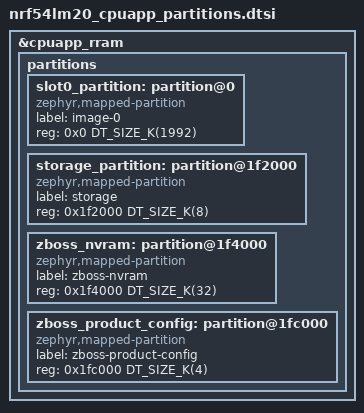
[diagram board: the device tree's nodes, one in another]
/*
 * Copyright (c) 2026 Nordic Semiconductor ASA
 *
 * SPDX-License-Identifier: LicenseRef-Nordic-5-Clause
 */

/delete-node/ &boot_partition;
/delete-node/ &slot0_partition;
/delete-node/ &slot1_partition;
/delete-node/ &storage_partition;

&cpuapp_rram {
	partitions {
		slot0_partition: partition@0 {
			compatible = "zephyr,mapped-partition";
			label = "image-0";
			reg = <0x0 DT_SIZE_K(1992)>;
		};

		storage_partition: partition@1f2000 {
			compatible = "zephyr,mapped-partition";
			label = "storage";
			reg = <0x1f2000 DT_SIZE_K(8)>;
		};

		zboss_nvram: partition@1f4000 {
			compatible = "zephyr,mapped-partition";
			label = "zboss-nvram";
			reg = <0x1f4000 DT_SIZE_K(32)>;
		};

		zboss_product_config: partition@1fc000 {
			compatible = "zephyr,mapped-partition";
			label = "zboss-product-config";
			reg = <0x1fc000 DT_SIZE_K(4)>;
		};
	};
};
